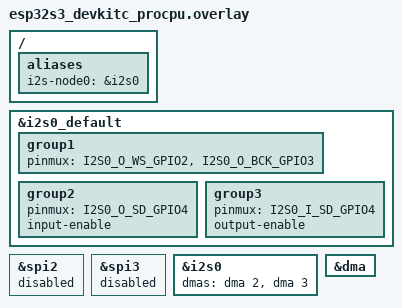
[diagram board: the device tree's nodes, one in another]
/*
 * Copyright (c) 2025 Espressif Systems (Shanghai) Co., Ltd.
 *
 * SPDX-License-Identifier: Apache-2.0
 */

/* i2s-node0 is the transmitter/receiver */

/ {
	aliases {
		i2s-node0 = &i2s0;
	};
};

/* GPIO35-37 and GPIO47-48 belong to the octal flash/PSRAM bus on the
 * devkitc variants with OPI memory; muxing i2s there kills XIP before
 * the console comes up. Use free header pins instead and keep spi2/3
 * away from them.
 */
&i2s0_default {
	group1 {
		pinmux = <I2S0_O_WS_GPIO2>,
			 <I2S0_O_BCK_GPIO3>;
	};

	group2 {
		pinmux = <I2S0_O_SD_GPIO4>;
		input-enable;
	};

	group3 {
		pinmux = <I2S0_I_SD_GPIO4>;
		output-enable;
	};
};

&spi2 {
	status = "disabled";
};

&spi3 {
	status = "disabled";
};

&i2s0 {
	status = "okay";

	dmas = <&dma 2>, <&dma 3>;
	dma-names = "rx", "tx";
};

&dma {
	status = "okay";
};
